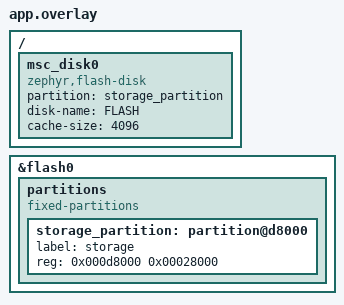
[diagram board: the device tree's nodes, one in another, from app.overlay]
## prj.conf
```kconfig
CONFIG_LOG=y
CONFIG_MAIN_STACK_SIZE=4096
CONFIG_DEBUG=y

CONFIG_FLASH=y
CONFIG_FLASH_MAP=y

CONFIG_FILE_SYSTEM=y
CONFIG_FILE_SYSTEM_MKFS=y
CONFIG_FILE_SYSTEM_LITTLEFS=y

#CONFIG_DISK_ACCESS=y
#CONFIG_DISK_DRIVERS=y
#CONFIG_DISK_DRIVER_FLASH=y

# Console
CONFIG_STDOUT_CONSOLE=y
CONFIG_USB_DEVICE_STACK=y
CONFIG_USB_CDC_ACM=y
CONFIG_USB_DEVICE_INITIALIZE_AT_BOOT=y
```

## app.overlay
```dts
/delete-node/ &storage_partition;
/delete-node/ &scratch_partition;

&flash0 {

	partitions {
		compatible = "fixed-partitions";
		#address-cells = <1>;
		#size-cells = <1>;

		storage_partition: partition@d8000 {
			label = "storage";
			reg = <0x000d8000 0x00028000>;
		};
	};
};

/ {
	msc_disk0 {
		status="okay";
		compatible = "zephyr,flash-disk";
		partition = <&storage_partition>;
		disk-name = "FLASH";
		/* cache-size == page erase size */
		cache-size = <4096>;
	};
};
```

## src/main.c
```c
/*
 * Copyright (c) 2022 Antmicro <www.antmicro.com>
 *
 * SPDX-License-Identifier: Apache-2.0
 */

#include <zephyr/kernel.h>
#include <zephyr/device.h>
#include <zephyr/fs/fs.h>
#include <zephyr/logging/log.h>

#if defined(CONFIG_FILE_SYSTEM_LITTLEFS) && defined(CONFIG_FAT_FILESYSTEM_ELM)
#error "Only one file system may be used at once in that sample."
#endif


#if defined(CONFIG_FILE_SYSTEM_LITTLEFS)

#include <zephyr/storage/flash_map.h>
#include <zephyr/fs/littlefs.h>

#define MKFS_FS_TYPE FS_LITTLEFS
#define MKFS_DEV_ID FIXED_PARTITION_ID(storage_partition)
#define MKFS_FLAGS 0

#elif defined(CONFIG_FAT_FILESYSTEM_ELM)

#include <zephyr/storage/flash_map.h>
#include <zephyr/storage/disk_access.h>
#include <ff.h>

#define MKFS_FS_TYPE FS_FATFS
//#define MKFS_DEV_ID "RAM:"
#define MKFS_DEV_ID "NAND:"
#define MKFS_FLAGS 0

#else
#error "No filesystem specified."
#endif

LOG_MODULE_REGISTER(main, LOG_LEVEL_INF);

int main(void)
{
	int rc;

	rc = fs_mkfs(MKFS_FS_TYPE, (uintptr_t)MKFS_DEV_ID, NULL, MKFS_FLAGS);

	if (rc < 0) {
		LOG_ERR("Format failed");
		return 0;
	}

	LOG_INF("Format successful");
	return 0;
}
```
